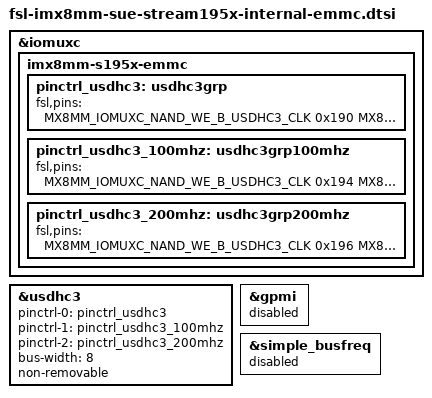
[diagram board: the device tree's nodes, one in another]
#include "fsl-imx8mm-sue-stream195x-internal.dtsi"

&iomuxc {
	imx8mm-s195x-emmc {
		pinctrl_usdhc3: usdhc3grp {
			fsl,pins = <
				MX8MM_IOMUXC_NAND_WE_B_USDHC3_CLK		0x190
				MX8MM_IOMUXC_NAND_WP_B_USDHC3_CMD		0x1d0
				MX8MM_IOMUXC_NAND_DATA04_USDHC3_DATA0		0x1d0
				MX8MM_IOMUXC_NAND_DATA05_USDHC3_DATA1		0x1d0
				MX8MM_IOMUXC_NAND_DATA06_USDHC3_DATA2		0x1d0
				MX8MM_IOMUXC_NAND_DATA07_USDHC3_DATA3		0x1d0
				MX8MM_IOMUXC_NAND_RE_B_USDHC3_DATA4		0x1d0
				MX8MM_IOMUXC_NAND_CE2_B_USDHC3_DATA5		0x1d0
				MX8MM_IOMUXC_NAND_CE3_B_USDHC3_DATA6		0x1d0
				MX8MM_IOMUXC_NAND_CLE_USDHC3_DATA7		0x1d0
				MX8MM_IOMUXC_NAND_CE1_B_USDHC3_STROBE 		0x190
			>;
		};

		pinctrl_usdhc3_100mhz: usdhc3grp100mhz {
			fsl,pins = <
				MX8MM_IOMUXC_NAND_WE_B_USDHC3_CLK		0x194
				MX8MM_IOMUXC_NAND_WP_B_USDHC3_CMD		0x1d4
				MX8MM_IOMUXC_NAND_DATA04_USDHC3_DATA0		0x1d4
				MX8MM_IOMUXC_NAND_DATA05_USDHC3_DATA1		0x1d4
				MX8MM_IOMUXC_NAND_DATA06_USDHC3_DATA2		0x1d4
				MX8MM_IOMUXC_NAND_DATA07_USDHC3_DATA3		0x1d4
				MX8MM_IOMUXC_NAND_RE_B_USDHC3_DATA4		0x1d4
				MX8MM_IOMUXC_NAND_CE2_B_USDHC3_DATA5		0x1d4
				MX8MM_IOMUXC_NAND_CE3_B_USDHC3_DATA6		0x1d4
				MX8MM_IOMUXC_NAND_CLE_USDHC3_DATA7		0x1d4
				MX8MM_IOMUXC_NAND_CE1_B_USDHC3_STROBE 		0x194
			>;
		};

		pinctrl_usdhc3_200mhz: usdhc3grp200mhz {
			fsl,pins = <
				MX8MM_IOMUXC_NAND_WE_B_USDHC3_CLK		0x196
				MX8MM_IOMUXC_NAND_WP_B_USDHC3_CMD		0x1d6
				MX8MM_IOMUXC_NAND_DATA04_USDHC3_DATA0		0x1d6
				MX8MM_IOMUXC_NAND_DATA05_USDHC3_DATA1		0x1d6
				MX8MM_IOMUXC_NAND_DATA06_USDHC3_DATA2		0x1d6
				MX8MM_IOMUXC_NAND_DATA07_USDHC3_DATA3		0x1d6
				MX8MM_IOMUXC_NAND_RE_B_USDHC3_DATA4		0x1d6
				MX8MM_IOMUXC_NAND_CE2_B_USDHC3_DATA5		0x1d6
				MX8MM_IOMUXC_NAND_CE3_B_USDHC3_DATA6		0x1d6
				MX8MM_IOMUXC_NAND_CLE_USDHC3_DATA7		0x1d6
				MX8MM_IOMUXC_NAND_CE1_B_USDHC3_STROBE 		0x196
			>;
		};
	};
};

&usdhc3 {
	pinctrl-names = "default", "state_100mhz", "state_200mhz";
	pinctrl-0 = <&pinctrl_usdhc3>;
	pinctrl-1 = <&pinctrl_usdhc3_100mhz>;
	pinctrl-2 = <&pinctrl_usdhc3_200mhz>;
	bus-width = <8>;
	non-removable;
	status = "okay";
};

&gpmi {
	status = "disabled";
};

&simple_busfreq {
	/*
	 * simple-busfreq requires proper configuration in imx-atf for it not to crash the board. As this will be done
	 * only later (see STREAMEIGHT-4327), disable it temporarily here.
	 */
	status = "disabled";
};
